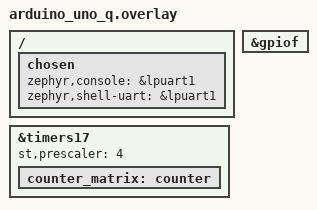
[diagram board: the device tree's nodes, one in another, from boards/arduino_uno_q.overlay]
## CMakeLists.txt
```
# Copyright (c) 2026 Jim Wyatt
# SPDX-License-Identifier: MIT
cmake_minimum_required(VERSION 3.20.0)
find_package(Zephyr REQUIRED HINTS $ENV{ZEPHYR_BASE})
project(hybrid_link)
target_sources(app PRIVATE src/main.c src/matrix.c src/bars.c src/status_leds.c)
# app_proto.h holds the MPU <-> MCU contract, shared with mcu/tests/, and
# bars.c is compiled a second time by mcu/tests/bars/ to run on the host.
target_include_directories(app PRIVATE include)
```

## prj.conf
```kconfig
# Copyright (c) 2026 Jim Wyatt
# SPDX-License-Identifier: MIT
# --- MPU <-> MCU link -------------------------------------------------------
CONFIG_GPIO=y
CONFIG_SERIAL=y
CONFIG_CONSOLE=y
CONFIG_UART_CONSOLE=y
CONFIG_PRINTK=y

# --- Interactive shell on the same UART the MPU reads (lpuart1) -------------
CONFIG_SHELL=y
CONFIG_SHELL_BACKEND_SERIAL=y
CONFIG_SHELL_PROMPT_UART="unoq:~$ "

# Built-in command sets: poke hardware without rebuilding.
CONFIG_GPIO_SHELL=y
CONFIG_I2C=y
CONFIG_I2C_SHELL=y
CONFIG_DEVICE_SHELL=y
CONFIG_KERNEL_SHELL=y

# --- SMP / MCUmgr over the shell transport ----------------------------------
# One UART serves console + shell + SMP, so SMP is multiplexed over the shell
# rather than claiming its own port.
# MCUMGR_TRANSPORT_SHELL needs these two or it silently disables itself
CONFIG_BASE64=y
CONFIG_CRC=y
CONFIG_NET_BUF=y
CONFIG_ZCBOR=y
CONFIG_MCUMGR=y
CONFIG_MCUMGR_TRANSPORT_SHELL=y
CONFIG_MCUMGR_GRP_OS=y
CONFIG_MCUMGR_GRP_OS_MCUMGR_PARAMS=y
CONFIG_MCUMGR_GRP_OS_TASKSTAT=y
CONFIG_MCUMGR_GRP_STAT=y
CONFIG_STATS=y
CONFIG_STATS_NAMES=y

CONFIG_MAIN_STACK_SIZE=2048

# --- 8x13 LED matrix --------------------------------------------------------
# Charlieplexed on PF0..PF10, refreshed from a TIM17 counter callback at 100kHz.
# See mcu/app/src/matrix.c and boards/arduino_uno_q.overlay.
CONFIG_COUNTER=y

# --- Persistent storage in storage_partition (128K, previously unused) ------
# Holds one byte: the panel orientation set by `app matrix flip`.
CONFIG_FLASH=y
CONFIG_FLASH_MAP=y
CONFIG_NVS=y
CONFIG_SETTINGS=y
CONFIG_SETTINGS_NVS=y

# --- MCUboot: app becomes a signed image in slot0, updatable over SMP -------
CONFIG_BOOTLOADER_MCUBOOT=y
CONFIG_MCUMGR_GRP_IMG=y
CONFIG_IMG_MANAGER=y
CONFIG_STREAM_FLASH=y
CONFIG_IMG_ERASE_PROGRESSIVELY=y
CONFIG_MCUMGR_GRP_OS_BOOTLOADER_INFO=y
```

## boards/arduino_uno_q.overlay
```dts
/*
 * Copyright (c) 2026 Jim Wyatt
 * SPDX-License-Identifier: MIT
 *
 * Route the Zephyr console to lpuart1 (PG7/PG8, with RTS/CTS) - the UART
 * physically wired to the Linux MPU, where it appears as /dev/ttyHS1.
 * usart1 (PB6/PB7) is the Arduino-header UART and is NOT the MPU link.
 */
/ {
	chosen {
		zephyr,console = &lpuart1;
		zephyr,shell-uart = &lpuart1;
	};
};

/*
 * The 8x13 LED panel. Upstream Zephyr's board does not describe it at all -
 * the wiring is only recorded in Arduino's core - so both halves are declared
 * here: the port the 104 LEDs are charlieplexed across, and the timer that
 * paces the refresh. See mcu/app/src/matrix.c.
 */

/* PF0..PF10 carry the panel. Enabling the port is what turns its clock on;
 * matrix.c then drives MODER/BSRR directly, because the pins have to change
 * direction every 10us. Nothing else in this build may claim PF0..PF10.
 */
&gpiof {
	status = "okay";
};

/* TIM17 is otherwise unused here, and is the timer Arduino's own firmware
 * picks for this job. Prescaler 4 divides the timer clock by 5, which leaves
 * counter_us_to_ticks() plenty of resolution for a 10us slot.
 */
&timers17 {
	status = "okay";
	st,prescaler = <4>;

	counter_matrix: counter {
		status = "okay";
	};
};
```

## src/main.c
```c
/*
 * Copyright (c) 2026 Jim Wyatt
 * SPDX-License-Identifier: MIT
 *
 * MCU side of the UNO Q hybrid link.
 *
 * Console + interactive shell + SMP/MCUmgr all share lpuart1, the UART wired
 * to the Linux MPU (/dev/ttyHS1). See boards/arduino_uno_q.overlay.
 *
 * The whole firmware is an "app" shell command group the MPU drives over that
 * link, plus one piece of state (panel orientation) persisted in NVS so it
 * survives power cycles and firmware updates.
 *
 * `app bars` is the MCU half of the CPU monitor: the MPU measures
 * (python/unoq/cpu.py), this side draws. See docs/mpu.md.
 *
 * There is no main loop. Everything that runs after init runs on its own:
 * the shell has a thread, and the panel is refreshed from a timer ISR inside
 * matrix.c. A loop here would have nothing to do but sleep, and printing from
 * one would fight the shell prompt.
 */
#include <zephyr/kernel.h>
#include <zephyr/shell/shell.h>
#include <zephyr/settings/settings.h>
#include <zephyr/dfu/mcuboot.h>
#include <stdlib.h>
#include <string.h>

#include "app_proto.h"
#include "bars.h"
#include "matrix.h"
#include "status_leds.h"

/* Panel state. `frame` is the last thing drawn, kept so a command that changes
 * orientation can redraw it rather than blanking the display. */
static uint8_t frame[APP_MATRIX_LEDS];
static uint8_t bar_pct[APP_BARS_MAX];
static int bar_count;
static uint8_t flip; /* 0/1, persisted - see APP_SETTINGS_FLIP */

/* --- persistent settings ------------------------------------------------- */

static int app_settings_set(const char *name, size_t len, settings_read_cb read_cb, void *cb_arg)
{
	if (settings_name_steq(name, "flip", NULL) && len == sizeof(flip)) {
		return read_cb(cb_arg, &flip, sizeof(flip)) > 0 ? 0 : -EINVAL;
	}
	return -ENOENT;
}

SETTINGS_STATIC_HANDLER_DEFINE(app, "app", NULL, app_settings_set, NULL, NULL);

/* --- shell commands: the MPU drives these over the serial link ----------- */

/* Every command handler starts here. LED 3 is the MCU saying "something
 * arrived and I dealt with it" - which is a different claim from Linux's "I
 * sent something", and the difference is exactly what you want when the link
 * has gone quiet and you are trying to work out which end stopped.
 */
static int cmd_app_status(const struct shell *sh, size_t argc, char **argv)
{
	status_leds_link_seen();
	ARG_UNUSED(argc);
	ARG_UNUSED(argv);
	shell_print(sh, APP_STATUS_FMT, k_uptime_get(), flip != 0, matrix_sweeps());
	return 0;
}

/* --- the LED panel -------------------------------------------------------- */

/* Redraw whatever is currently meant to be on screen. Called after anything
 * that changes how a frame maps to pixels, so orientation takes effect
 * immediately instead of at the next update from the MPU. */
static void redraw(void)
{
	if (bar_count > 0) {
		app_bars_render(bar_pct, bar_count, flip != 0, frame);
		matrix_draw(frame);
	}
}

static int cmd_app_bars(const struct shell *sh, size_t argc, char **argv)
{
	status_leds_link_seen();
	int n = (int)argc - 1;

	if (!app_bars_count_valid(n)) {
		shell_error(sh, "usage: app bars <pct> [pct ...] (1..%d values)", APP_BARS_MAX);
		return -EINVAL;
	}

	/* Validate everything before drawing anything: a partly-applied update
	 * would show a frame that never corresponded to a real measurement. */
	for (int i = 0; i < n; i++) {
		int pct = atoi(argv[i + 1]);

		if (!app_bars_pct_valid(pct)) {
			shell_error(sh, "bar %d: %d outside 0..%d", i, pct, APP_BARS_PCT_MAX);
			return -EINVAL;
		}
		bar_pct[i] = (uint8_t)pct;
	}
	bar_count = n;

	redraw();
	shell_print(sh, "ok bars=%d", n);
	return 0;
}

/* Light exactly one LED. This is how you find out which corner row 0, column 0
 * really is on a board in front of you - the answer depends on which way round
 * it is mounted, so it is not something the firmware can assume. */
static int cmd_app_matrix_px(const struct shell *sh, size_t argc, char **argv)
{
	status_leds_link_seen();
	int row = atoi(argv[1]);
	int col = atoi(argv[2]);
	int level = atoi(argv[3]);
	int idx;

	ARG_UNUSED(argc);

	if (!app_matrix_pixel_valid(row, col)) {
		shell_error(sh, "row 0..%d, col 0..%d", APP_MATRIX_ROWS - 1, APP_MATRIX_COLS - 1);
		return -EINVAL;
	}
	if (!app_matrix_level_valid(level)) {
		shell_error(sh, "level 0..%d", APP_MATRIX_MAX_LEVEL);
		return -EINVAL;
	}

	/* Same coordinates as `app bars`, flip included, so that once flip is
	 * right for the panel it is right for both. */
	idx = row * APP_MATRIX_COLS + col;
	if (flip) {
		idx = APP_MATRIX_LEDS - 1 - idx;
	}

	memset(frame, 0, sizeof(frame));
	frame[idx] = (uint8_t)level;
	bar_count = 0; /* the bars are gone; do not let a redraw resurrect them */
	matrix_draw(frame);

	shell_print(sh, "ok px row=%d col=%d level=%d", row, col, level);
	return 0;
}

static int cmd_app_matrix_flip(const struct shell *sh, size_t argc, char **argv)
{
	status_leds_link_seen();
	ARG_UNUSED(argc);
	ARG_UNUSED(argv);

	flip = !flip;
	settings_save_one(APP_SETTINGS_FLIP, &flip, sizeof(flip));
	redraw();

	shell_print(sh, "ok flip=%d", flip);
	return 0;
}

static int cmd_app_matrix_off(const struct shell *sh, size_t argc, char **argv)
{
	status_leds_link_seen();
	ARG_UNUSED(argc);
	ARG_UNUSED(argv);

	bar_count = 0;
	matrix_off();
	shell_print(sh, "ok matrix off");
	return 0;
}

SHELL_STATIC_SUBCMD_SET_CREATE(
	matrix_cmds,
	SHELL_CMD_ARG(px, NULL, "Light one LED: app matrix px <row> <col> <level>",
		      cmd_app_matrix_px, 4, 0),
	SHELL_CMD(flip, NULL, "Rotate the panel 180 degrees (persisted)", cmd_app_matrix_flip),
	SHELL_CMD(off, NULL, "Blank the panel and stop the refresh", cmd_app_matrix_off),
	SHELL_SUBCMD_SET_END);

SHELL_STATIC_SUBCMD_SET_CREATE(app_cmds,
			       SHELL_CMD(status, NULL, "uptime, panel orientation, refresh sweeps",
					 cmd_app_status),
			       SHELL_CMD_ARG(bars, NULL, "Draw CPU bars: app bars <pct> [pct ...]",
					     cmd_app_bars, 2, APP_BARS_MAX - 1),
			       SHELL_CMD(matrix, &matrix_cmds, "LED panel control", NULL),
			       SHELL_SUBCMD_SET_END);
SHELL_CMD_REGISTER(app, &app_cmds, "UNO Q application commands", NULL);

/* --- main ---------------------------------------------------------------- */

int main(void)
{
	printk("\n=== UNO Q MCU up: %s ===\n", CONFIG_BOARD_TARGET);

	/* Load the persisted panel orientation before the matrix comes up, so
	 * the first frame drawn is already the right way round. */
	if (settings_subsys_init() != 0 || settings_load() != 0) {
		printk("settings unavailable - panel orientation not persisted\n");
	}

	/* The panel stays dark until something draws on it, so a failure here
	 * costs the LED matrix and nothing else - the link and the shell both
	 * still come up. */
	/* LED 3 and LED 4. A board without them still runs everything else, so
	 * this only reports. */
	status_leds_init();

	/* LED 3 answers the question you actually have after an update: is this
	 * the firmware that will still be here after the next reset? MCUboot
	 * runs a new image unconfirmed the first time, and reverts it unless
	 * something confirms it - so "unconfirmed" is a real, temporary,
	 * invisible state, and yellow is the only place it is visible without
	 * reading the slot table over the wire. */
	bool confirmed = boot_is_img_confirmed();

	status_leds_set_image_confirmed(confirmed);
	printk("status LEDs %s, image %s\n", status_leds_present() ? "ready" : "unavailable",
	       confirmed ? "confirmed" : "UNCONFIRMED (reverts on next reset)");

	if (matrix_init() == 0) {
		printk("LED matrix ready (%dx%d, flip=%d)\n", APP_MATRIX_ROWS, APP_MATRIX_COLS,
		       flip != 0);
	} else {
		printk("LED matrix unavailable\n");
		status_leds_set_fault();
	}

	return 0;
}
```

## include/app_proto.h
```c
/*
 * Copyright (c) 2026 Jim Wyatt
 * SPDX-License-Identifier: MIT
 *
 * The MPU <-> MCU contract, in one place.
 *
 * Everything here is consumed by three parties that must agree:
 *
 *   - mcu/app/src/main.c        produces the status line, validates bars
 *   - mcu/tests/link_protocol/  tests these definitions directly
 *   - python/unoq/mcu.py        parses the status line, calls `app bars`
 *
 * The definitions used to be duplicated: main.c had the range check and the
 * format string, and the test had its own copy of both. A copy cannot fail
 * when the original changes, so the test proved nothing about the firmware.
 * Include this from both instead.
 *
 * A change here is a protocol change - update unoq/mcu.py and its tests too.
 */
#ifndef APP_PROTO_H
#define APP_PROTO_H

#include <stdbool.h>

/* The `app status` line, parsed by unoq.MCU.status() into a dict.
 *
 * Format is "key=value" pairs separated by single spaces. The parser splits on
 * whitespace and then on the first '=', so a value must never contain either.
 */
#define APP_STATUS_FMT    "uptime_ms=%lld flip=%d sweeps=%u"
#define APP_STATUS_FIELDS 3

/* --- LED matrix ----------------------------------------------------------
 *
 * 104 blue LEDs, charlieplexed on PF0..PF10 and refreshed by a timer ISR - see
 * mcu/app/src/matrix.c. Geometry is fixed by the panel, so it lives here where
 * both sides and the tests can see it.
 *
 * LED index i is row-major: row = i / APP_MATRIX_COLS, col = i % APP_MATRIX_COLS.
 * Row 0 / column 0 is the corner nearest the USB-C connectors; `app matrix px`
 * exists to confirm that on a board rather than trusting this comment.
 */
#define APP_MATRIX_ROWS 8
#define APP_MATRIX_COLS 13
#define APP_MATRIX_LEDS (APP_MATRIX_ROWS * APP_MATRIX_COLS)

/* 3-bit grayscale: 0 is off, APP_MATRIX_MAX_LEVEL is fully on. */
#define APP_MATRIX_MAX_LEVEL 7

/* Refresh sweeps per second while the panel is on - one sweep per pass over
 * all 104 LEDs, at the 10us slot matrix.c programs. `app status` reports the
 * running count, and this is what to expect it to climb by each second: it is
 * the only evidence from the far end of a serial cable that the panel is
 * really being driven. See matrix.h. */
#define APP_MATRIX_SWEEPS_PER_S 962

static inline bool app_matrix_level_valid(int level)
{
	return level >= 0 && level <= APP_MATRIX_MAX_LEVEL;
}

static inline bool app_matrix_pixel_valid(int row, int col)
{
	return row >= 0 && row < APP_MATRIX_ROWS && col >= 0 && col < APP_MATRIX_COLS;
}

/* --- CPU bars -------------------------------------------------------------
 *
 * `app bars <pct> [pct ...]` draws one vertical bar per value. The MPU sends
 * whole percentages - it owns the measurement (python/unoq/cpu.py), the MCU
 * owns the pixels. Keeping the wire format integer percent means the shell
 * command is still something a human can type by hand while debugging.
 *
 * The cap is the panel's, not the host's. Bars are one column wide at minimum
 * and always separated by one blank column, so n bars need 2n-1 columns: 7 is
 * the most that fit. A host with more cores than that has to aggregate.
 */
#define APP_BARS_MAX     ((APP_MATRIX_COLS + 1) / 2)
#define APP_BARS_PCT_MAX 100

static inline bool app_bars_pct_valid(int pct)
{
	return pct >= 0 && pct <= APP_BARS_PCT_MAX;
}

static inline bool app_bars_count_valid(int n)
{
	return n >= 1 && n <= APP_BARS_MAX;
}

/* Settings key (NVS, storage_partition).
 *
 * The panel's orientation is persisted because it is a property of how the
 * board is mounted, not of the running session: whoever fits the board decides
 * it once with `app matrix flip` and it survives power cycles and updates.
 */
#define APP_SETTINGS_FLIP "app/flip"

#endif /* APP_PROTO_H */
```

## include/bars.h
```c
/*
 * Copyright (c) 2026 Jim Wyatt
 * SPDX-License-Identifier: MIT
 *
 * Turning percentages into pixels.
 *
 * Deliberately free of Zephyr and of hardware: this is arithmetic, so it is
 * compiled straight into mcu/tests/bars/ and runs on the host. The half of the
 * feature that cannot be tested that way - charlieplexing PF0..PF10 from a
 * timer ISR - lives in matrix.h and stays as thin as possible.
 */
#ifndef BARS_H
#define BARS_H

#include <stdbool.h>
#include <stdint.h>

#include "app_proto.h"

/* Where n bars sit on the 13-column panel.
 *
 * Bars are uniform width with a one-column gap, and the whole group is
 * centred: leftovers show up as margin, never as one fatter bar.
 */
struct app_bars_layout {
	int width; /* columns per bar, >= 1 */
	int left;  /* blank columns before the first bar */
};

/* Compute the layout for n bars. Returns false (and leaves *out alone) if n is
 * outside 1..APP_BARS_MAX. */
bool app_bars_layout(int n, struct app_bars_layout *out);

/* Which column the i-th bar starts at, given a layout. */
static inline int app_bars_column(const struct app_bars_layout *l, int i)
{
	return l->left + i * (l->width + 1);
}

/*
 * Render n percentages as vertical bars into a APP_MATRIX_LEDS grayscale
 * framebuffer (one byte per LED, 0..APP_MATRIX_MAX_LEVEL), clearing it first.
 *
 * Height uses the grayscale as a vernier: a bar is whole rows at full
 * brightness plus one partial row dimmed in proportion to the remainder. Eight
 * rows would otherwise quantise the reading to 12.5% steps, which for a CPU
 * meter is the difference between "idle" and "a core is busy".
 *
 * rotate180 mirrors the panel for a board viewed from the other side. It is a
 * true 180-degree rotation, so bars grow the other way *and* run right-to-left,
 * which is what you want if you turned the board around rather than the image.
 *
 * pct values outside 0..APP_BARS_PCT_MAX are clamped, and n outside
 * 1..APP_BARS_MAX renders an empty frame - a display that shows nothing is a
 * better failure than one that shows a wrong number confidently.
 */
void app_bars_render(const uint8_t *pct, int n, bool rotate180, uint8_t *frame);

#endif /* BARS_H */
```

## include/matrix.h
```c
/*
 * Copyright (c) 2026 Jim Wyatt
 * SPDX-License-Identifier: MIT
 *
 * The 8x13 LED panel.
 *
 * Everything hardware about the matrix is behind these four calls, so the
 * interesting half of the feature (bars.h) stays testable on the host.
 */
#ifndef MATRIX_H
#define MATRIX_H

#include <stdbool.h>
#include <stdint.h>

/* Claim the GPIO port and the refresh timer. Does not light anything and does
 * not start the ISR - the first matrix_draw() does that. Returns 0, or a
 * negative errno if the devicetree does not give us what we need. */
int matrix_init(void);

/* Show a frame: APP_MATRIX_LEDS bytes, one brightness level (0..
 * APP_MATRIX_MAX_LEVEL) per LED, row-major. The buffer is copied. */
void matrix_draw(const uint8_t *levels);

/* Stop refreshing and release the pins. matrix_draw() restarts it. */
void matrix_off(void);

/*
 * Completed refresh sweeps since boot - one per pass over all 104 LEDs.
 *
 * This is the only way to tell from the far end of a serial cable that the
 * panel is really being refreshed: nothing else about a charlieplexed display
 * is observable without looking at it. A stalled count means the timer never
 * started; a count climbing at ~962/s means the ISR is running to schedule.
 */
uint32_t matrix_sweeps(void);

#endif /* MATRIX_H */
```

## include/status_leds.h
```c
/*
 * Copyright (c) 2026 Jim Wyatt
 * SPDX-License-Identifier: MIT
 *
 * The two RGB LEDs wired to the STM32 rather than to Linux.
 *
 * The board has four. Linux drives LED 1 and LED 2 through /sys/class/leds and
 * shows connectivity and unit health there; LED 3 and LED 4 are on this side,
 * named led3_red/green/blue and led4_* in Zephyr's board definition.
 *
 * WHAT THEY SHOW, AND WHY NOT THE OBVIOUS THINGS
 * ----------------------------------------------
 * The first attempt used them for link traffic and eMMC activity. Both were
 * wrong, and the board made it obvious:
 *
 *   Blinking on every command received made LED 3 a CLOCK. cpubars sends a
 *   frame every 0.5s, so the LED blinked every 0.5s, forever, saying only
 *   "the demo is running" - which the matrix already says, in more detail.
 *   An indicator whose period is set by someone else's timer carries no
 *   information.
 *
 *   eMMC activity cannot be shown from here at any useful resolution. Linux
 *   samples the counter twice a second and pushes the answer down a 115200
 *   link; a real activity light flickers on individual transfers. What you got
 *   was a lamp that sat on through a copy and off otherwise - which the CPU
 *   bars beside it already imply.
 *
 * So both now show things ONLY THIS CHIP KNOWS, and that change slowly enough
 * that every transition means something:
 *
 *   LED 3   the firmware's own identity.
 *           green   running a CONFIRMED image - this is what stays after a reset
 *           yellow  running an UNCONFIRMED image, on MCUboot probation. The
 *                   next reset reverts it. Invisible otherwise unless you go
 *                   and read the slot table, and precisely what you want to see
 *                   on the hardware after an update.
 *           red     a subsystem failed to start (see main.c)
 *
 *   LED 4   whether the MPU is still talking.
 *           green   heard from Linux within the last few seconds
 *           red     silent for longer than that
 *
 * LED 4 is the inverse of the blink it replaces. A tick tells you nothing; the
 * tick STOPPING is the news, and it is news Linux cannot deliver - a host that
 * has stopped talking cannot report that it stopped talking. This is the only
 * indicator on the board that says something about the other chip's health.
 */

#ifndef STATUS_LEDS_H
#define STATUS_LEDS_H

#include <stdbool.h>

/* How long the MPU may be quiet before LED 4 calls the link stale.
 *
 * cpubars draws twice a second, and the MCU shell is also poked by hand, so a
 * few seconds of silence is comfortably abnormal without being twitchy about a
 * host that paused to do something else.
 */
#define STATUS_LINK_STALE_MS 4000

/** Claim the GPIOs. Safe on a board without them: everything below then does
 *  nothing, and status_leds_present() says so.
 */
void status_leds_init(void);

/** Note that something arrived from the MPU. Cheap - a timestamp, no I/O. */
void status_leds_link_seen(void);

/** LED 3: green for a confirmed image, yellow for one still on probation. */
void status_leds_set_image_confirmed(bool confirmed);

/** LED 3: red, and it stays red. For a subsystem that failed to come up. */
void status_leds_set_fault(void);

/** True if the GPIOs were found and claimed. */
bool status_leds_present(void);

#endif /* STATUS_LEDS_H */
```

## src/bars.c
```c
/*
 * Copyright (c) 2026 Jim Wyatt
 * SPDX-License-Identifier: MIT
 *
 * Percentages -> grayscale pixels. See include/bars.h for the contract.
 *
 * No Zephyr headers on purpose: mcu/tests/bars/ compiles this file directly
 * and runs it on the host.
 */
#include <string.h>

#include "bars.h"

bool app_bars_layout(int n, struct app_bars_layout *out)
{
	int width, used;

	if (!app_bars_count_valid(n)) {
		return false;
	}

	/* n bars plus n-1 single-column gaps have to fit in the panel. The
	 * APP_BARS_MAX cap guarantees this leaves at least one column per bar.
	 */
	width = (APP_MATRIX_COLS - (n - 1)) / n;
	used = n * width + (n - 1);

	out->width = width;
	out->left = (APP_MATRIX_COLS - used) / 2;
	return true;
}

/* Fill one bar's columns, bottom-up, in unrotated coordinates. */
static void draw_bar(uint8_t *frame, int col, int width, int pct)
{
	int units, full, part, row, c;

	if (pct < 0) {
		pct = 0;
	} else if (pct > APP_BARS_PCT_MAX) {
		pct = APP_BARS_PCT_MAX;
	}

	/* Height in units of one brightness step, so the division that loses
	 * precision happens once, here, rather than per row. */
	units = pct * APP_MATRIX_ROWS * APP_MATRIX_MAX_LEVEL / APP_BARS_PCT_MAX;
	full = units / APP_MATRIX_MAX_LEVEL;
	part = units % APP_MATRIX_MAX_LEVEL;

	for (row = 0; row < full; row++) {
		for (c = col; c < col + width; c++) {
			frame[(APP_MATRIX_ROWS - 1 - row) * APP_MATRIX_COLS + c] =
				APP_MATRIX_MAX_LEVEL;
		}
	}

	/* The partial row only exists below the top of the panel; at 100% the
	 * remainder is zero anyway, so this never clips a full bar. */
	if (part > 0 && full < APP_MATRIX_ROWS) {
		for (c = col; c < col + width; c++) {
			frame[(APP_MATRIX_ROWS - 1 - full) * APP_MATRIX_COLS + c] = (uint8_t)part;
		}
	}
}

void app_bars_render(const uint8_t *pct, int n, bool rotate180, uint8_t *frame)
{
	struct app_bars_layout layout;
	int i;

	memset(frame, 0, APP_MATRIX_LEDS);

	if (!app_bars_layout(n, &layout)) {
		return;
	}

	for (i = 0; i < n; i++) {
		draw_bar(frame, app_bars_column(&layout, i), layout.width, pct[i]);
	}

	/* Row-major indexing makes a 180-degree rotation a plain reversal. */
	if (rotate180) {
		for (i = 0; i < APP_MATRIX_LEDS / 2; i++) {
			uint8_t tmp = frame[i];

			frame[i] = frame[APP_MATRIX_LEDS - 1 - i];
			frame[APP_MATRIX_LEDS - 1 - i] = tmp;
		}
	}
}
```

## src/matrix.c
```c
/*
 * Copyright (c) 2026 Jim Wyatt
 * SPDX-License-Identifier: MIT
 *
 * Charlieplex driver for the UNO Q's 8x13 LED panel.
 *
 * The 104 LEDs hang off eleven pins, PF0..PF10, as ordered pairs: LED n is lit
 * by driving one pin high, one low, and leaving the other nine floating. Only
 * one LED is ever on; the illusion of a picture is entirely persistence of
 * vision, which is why the refresh runs from a timer ISR and not a thread.
 *
 * WHY REGISTER ACCESS, NOT THE GPIO API
 * -------------------------------------
 * Charlieplexing needs pins to change *direction*, not just level, once every
 * 10us. gpio_pin_configure_dt() is the API for that and it is far too heavy to
 * call 100k times a second - it re-resolves the port, takes a lock and walks
 * the pinctrl tables. Writing MODER and BSRR directly is a two-instruction
 * version of the same thing. The port is still claimed through the devicetree
 * (see matrix_init) so that Zephyr enables its clock and nothing else in the
 * build believes PF0..PF10 are free.
 *
 * The pin pairing and the 10us slot come from Arduino's own implementation for
 * this panel (ArduinoCore-zephyr, loader/matrix.inc) - it is the only
 * description of how this hardware is wired that exists. The grayscale is not
 * theirs: see the phase comment below.
 */
#include <zephyr/kernel.h>
#include <zephyr/device.h>
#include <zephyr/drivers/counter.h>
#include <soc.h>
#include <string.h>

#include "app_proto.h"
#include "matrix.h"

/* PF0..PF10. Eleven pins give 11*10 = 110 ordered pairs, of which the panel
 * uses the first 104. */
#define MATRIX_PINS 11

/* MODER holds two bits per pin, so our eleven pins occupy the low 22. Masking
 * exactly those leaves PF11..PF15 - which reach the Arduino header - untouched.
 */
#define MATRIX_MODER_MASK ((uint32_t)((1ULL << (2 * MATRIX_PINS)) - 1))

/* One LED per slot: 104 slots is a 1.04ms sweep, and a grayscale cycle is
 * APP_MATRIX_MAX_LEVEL sweeps, so the panel refreshes at ~137Hz. */
#define MATRIX_SLOT_US 10

#define MATRIX_TIMER DT_NODELABEL(counter_matrix)
#define MATRIX_PORT  DT_NODELABEL(gpiof)

static const struct device *const timer = DEVICE_DT_GET(MATRIX_TIMER);
static const struct device *const port = DEVICE_DT_GET(MATRIX_PORT);

static uint8_t anode[APP_MATRIX_LEDS];   /* pin driven high for LED n */
static uint8_t cathode[APP_MATRIX_LEDS]; /* pin driven low for LED n */

static uint8_t framebuffer[APP_MATRIX_LEDS];
static bool ready;   /* matrix_init() succeeded; the devices are usable */
static bool running; /* the refresh timer is going */
static uint32_t sweeps;

/* Enumerate the charlieplex pairs in panel order: for each new pin, pair it
 * with every lower-numbered one, both ways round. Generating the table beats
 * transcribing 104 literals - there is no typo to make. */
static void build_pin_table(void)
{
	int idx = 0;

	for (int hi = 1; hi < MATRIX_PINS; hi++) {
		for (int lo = 0; lo < hi; lo++) {
			if (idx < APP_MATRIX_LEDS) {
				anode[idx] = (uint8_t)lo;
				cathode[idx] = (uint8_t)hi;
				idx++;
			}
			if (idx < APP_MATRIX_LEDS) {
				anode[idx] = (uint8_t)hi;
				cathode[idx] = (uint8_t)lo;
				idx++;
			}
		}
	}
}

static inline void all_pins_floating(void)
{
	GPIOF->MODER &= ~MATRIX_MODER_MASK;
}

/*
 * One slot. Every LED gets a slot in every sweep; a level-L LED is actually
 * driven in L of the APP_MATRIX_MAX_LEVEL sweeps that make up a grayscale
 * cycle, so brightness is L/7 duty at a flicker-free rate. Comparing against a
 * per-sweep phase rather than a free-running counter keeps the LEDs of one
 * level in step, which is what stops a dim frame from shimmering.
 */
static void matrix_tick(const struct device *dev, void *user_data)
{
	static uint16_t idx;
	static uint8_t phase;
	uint8_t level;

	ARG_UNUSED(dev);
	ARG_UNUSED(user_data);

	/* Unconditionally first: the previous LED has to stop conducting
	 * before the next pair is driven, or its neighbours ghost. */
	all_pins_floating();

	level = framebuffer[idx];
	if (level > phase) {
		uint32_t a = anode[idx];
		uint32_t c = cathode[idx];

		/* Levels before directions - BSRR on a floating pin is
		 * harmless, but driving before the level is set would emit a
		 * glimpse of whatever ODR held. */
		GPIOF->BSRR = BIT(a) | BIT(c + 16);
		GPIOF->MODER |= BIT(a * 2) | BIT(c * 2);
	}

	if (++idx == APP_MATRIX_LEDS) {
		idx = 0;
		sweeps++;
		phase = (phase + 1) % APP_MATRIX_MAX_LEVEL;
	}
}

static int matrix_start(void)
{
	struct counter_top_cfg top_cfg = {
		.ticks = counter_us_to_ticks(timer, MATRIX_SLOT_US),
		.callback = matrix_tick,
		.user_data = NULL,
		.flags = 0,
	};
	int err;

	if (top_cfg.ticks == 0 || top_cfg.ticks > counter_get_max_top_value(timer)) {
		return -ERANGE;
	}

	err = counter_start(timer);
	if (err != 0) {
		return err;
	}

	err = counter_set_top_value(timer, &top_cfg);
	if (err != 0) {
		counter_stop(timer);
		return err;
	}

	running = true;
	return 0;
}

int matrix_init(void)
{
	if (!device_is_ready(port) || !device_is_ready(timer)) {
		return -ENODEV;
	}

	build_pin_table();
	all_pins_floating();
	ready = true;
	return 0;
}

void matrix_draw(const uint8_t *levels)
{
	unsigned int key;

	/* Without the devicetree nodes there is no port to write and no timer
	 * to pace it; going further would call counter_*() on a device that
	 * never initialised. */
	if (!ready) {
		return;
	}

	key = irq_lock();
	memcpy(framebuffer, levels, sizeof(framebuffer));
	irq_unlock(key);

	if (!running) {
		/* Nothing to report to: a panel that will not start shows
		 * nothing, which is already the visible symptom. */
		(void)matrix_start();
	}
}

void matrix_off(void)
{
	if (!ready) {
		return;
	}
	if (running) {
		counter_stop(timer);
		running = false;
	}
	all_pins_floating();
	memset(framebuffer, 0, sizeof(framebuffer));
}

uint32_t matrix_sweeps(void)
{
	return sweeps;
}
```

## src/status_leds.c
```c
/*
 * Copyright (c) 2026 Jim Wyatt
 * SPDX-License-Identifier: MIT
 *
 * LED 3 and LED 4 - the two RGB LEDs on the MCU side. See status_leds.h.
 */

#include "status_leds.h"

#include <zephyr/drivers/gpio.h>
#include <zephyr/kernel.h>

/* The board definition describes these as gpio-leds children. Using the node
 * labels rather than the led0/led1 aliases on purpose: the aliases only cover
 * two of the six channels (led3_green and led3_red), and colour is the whole
 * point here.
 */
#define LED_SPEC(node) GPIO_DT_SPEC_GET_OR(DT_NODELABEL(node), gpios, {0})

static const struct gpio_dt_spec led3[] = {
	LED_SPEC(led3_red),
	LED_SPEC(led3_green),
	LED_SPEC(led3_blue),
};
static const struct gpio_dt_spec led4[] = {
	LED_SPEC(led4_red),
	LED_SPEC(led4_green),
	LED_SPEC(led4_blue),
};

enum { CH_RED = 0, CH_GREEN = 1, CH_BLUE = 2 };

static bool ready;

/* Turning the blink off is deferred rather than slept through: this is called
 * from the shell thread, and a 40 ms sleep there would add 40 ms to every
 * command's round trip - measurable, and for a status LED, absurd.
 */
static void link_blink_off(struct k_work *work);
static K_WORK_DELAYABLE_DEFINE(link_off_work, link_blink_off);

static void set_chan(const struct gpio_dt_spec *spec, int on)
{
	if (spec->port == NULL) {
		return;
	}
	(void)gpio_pin_set_dt(spec, on);
}

static void set_rgb(const struct gpio_dt_spec *led, int r, int g, int b)
{
	set_chan(&led[CH_RED], r);
	set_chan(&led[CH_GREEN], g);
	set_chan(&led[CH_BLUE], b);
}

static bool claim(const struct gpio_dt_spec *led, size_t n)
{
	bool any = false;

	for (size_t i = 0; i < n; i++) {
		if (led[i].port == NULL) {
			continue;
		}
		if (!gpio_is_ready_dt(&led[i])) {
			continue;
		}
		if (gpio_pin_configure_dt(&led[i], GPIO_OUTPUT_INACTIVE) != 0) {
			continue;
		}
		any = true;
	}
	return any;
}

void status_leds_init(void)
{
	bool a = claim(led3, ARRAY_SIZE(led3));
	bool b = claim(led4, ARRAY_SIZE(led4));

	ready = a || b;
	if (!ready) {
		return;
	}
	set_rgb(led3, 0, 0, 0);
	set_rgb(led4, 0, 0, 0);
}

bool status_leds_present(void)
{
	return ready;
}

static void link_blink_off(struct k_work *work)
{
	ARG_UNUSED(work);
	set_rgb(led3, 0, 0, 0);
}

void status_leds_link_activity(void)
{
	if (!ready) {
		return;
	}
	set_rgb(led3, 0, 0, 1);
	/* Reschedule rather than stack: a burst of commands should look like a
	 * flicker that stays lit while the burst lasts, not a queue of work
	 * items each turning it off at its own moment.
	 */
	(void)k_work_reschedule(&link_off_work, K_MSEC(STATUS_LED_BLINK_MS));
}

void status_leds_set_io(bool busy)
{
	if (!ready) {
		return;
	}
	/* Green, not blue: LED 3 is already blue for link traffic, and two
	 * LEDs blinking the same colour next to each other are impossible to
	 * tell apart at a glance.
	 */
	set_rgb(led4, 0, busy ? 1 : 0, 0);
}
```
